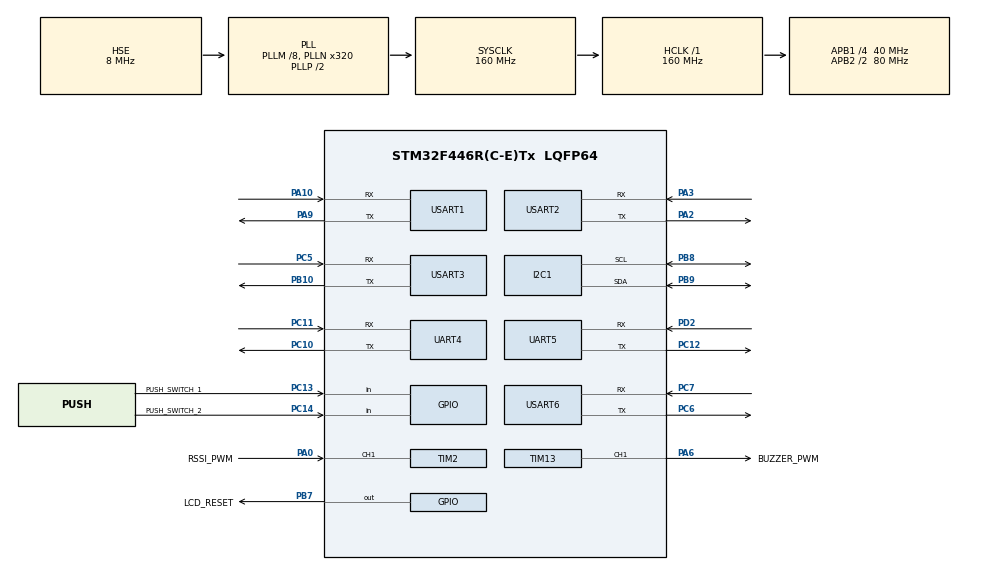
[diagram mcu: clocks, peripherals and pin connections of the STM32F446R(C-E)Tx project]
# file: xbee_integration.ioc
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Dma.Request0=USART1_RX
Dma.Request1=USART1_TX
Dma.Request10=UART4_RX
Dma.Request11=UART4_TX
Dma.Request2=USART2_RX
Dma.Request3=USART2_TX
Dma.Request4=USART3_RX
Dma.Request5=USART3_TX
Dma.Request6=USART6_RX
Dma.Request7=USART6_TX
Dma.Request8=UART5_RX
Dma.Request9=UART5_TX
Dma.UART4_RX.10.Direction=DMA_PERIPH_TO_MEMORY
Dma.UART4_RX.10.FIFOMode=DMA_FIFOMODE_DISABLE
Dma.UART4_RX.10.Instance=DMA1_Stream2
Dma.UART4_RX.10.MemDataAlignment=DMA_MDATAALIGN_BYTE
Dma.UART4_RX.10.MemInc=DMA_MINC_ENABLE
Dma.UART4_RX.10.Mode=DMA_CIRCULAR
Dma.UART4_RX.10.PeriphDataAlignment=DMA_PDATAALIGN_BYTE
Dma.UART4_RX.10.PeriphInc=DMA_PINC_DISABLE
Dma.UART4_RX.10.Priority=DMA_PRIORITY_LOW
Dma.UART4_TX.11.Direction=DMA_MEMORY_TO_PERIPH
Dma.UART4_TX.11.FIFOMode=DMA_FIFOMODE_DISABLE
Dma.UART4_TX.11.Instance=DMA1_Stream4
Dma.UART4_TX.11.MemDataAlignment=DMA_MDATAALIGN_BYTE
Dma.UART4_TX.11.MemInc=DMA_MINC_ENABLE
Dma.UART4_TX.11.Mode=DMA_NORMAL
Dma.UART4_TX.11.PeriphDataAlignment=DMA_PDATAALIGN_BYTE
Dma.UART4_TX.11.PeriphInc=DMA_PINC_DISABLE
Dma.UART4_TX.11.Priority=DMA_PRIORITY_MEDIUM
Dma.UART5_RX.8.Direction=DMA_PERIPH_TO_MEMORY
Dma.UART5_RX.8.FIFOMode=DMA_FIFOMODE_DISABLE
Dma.UART5_RX.8.Instance=DMA1_Stream0
Dma.UART5_RX.8.MemDataAlignment=DMA_MDATAALIGN_BYTE
Dma.UART5_RX.8.MemInc=DMA_MINC_ENABLE
Dma.UART5_RX.8.Mode=DMA_NORMAL
Dma.UART5_RX.8.PeriphDataAlignment=DMA_PDATAALIGN_BYTE
Dma.UART5_RX.8.PeriphInc=DMA_PINC_DISABLE
Dma.UART5_RX.8.Priority=DMA_PRIORITY_LOW
Dma.UART5_TX.9.Direction=DMA_MEMORY_TO_PERIPH
Dma.UART5_TX.9.FIFOMode=DMA_FIFOMODE_DISABLE
Dma.UART5_TX.9.Instance=DMA1_Stream7
Dma.UART5_TX.9.MemDataAlignment=DMA_MDATAALIGN_BYTE
Dma.UART5_TX.9.MemInc=DMA_MINC_ENABLE
Dma.UART5_TX.9.Mode=DMA_NORMAL
Dma.UART5_TX.9.PeriphDataAlignment=DMA_PDATAALIGN_BYTE
Dma.UART5_TX.9.PeriphInc=DMA_PINC_DISABLE
Dma.UART5_TX.9.Priority=DMA_PRIORITY_MEDIUM
Dma.USART1_RX.0.Direction=DMA_PERIPH_TO_MEMORY
Dma.USART1_RX.0.FIFOMode=DMA_FIFOMODE_DISABLE
Dma.USART1_RX.0.Instance=DMA2_Stream2
Dma.USART1_RX.0.MemDataAlignment=DMA_MDATAALIGN_BYTE
Dma.USART1_RX.0.MemInc=DMA_MINC_ENABLE
Dma.USART1_RX.0.Mode=DMA_CIRCULAR
Dma.USART1_RX.0.PeriphDataAlignment=DMA_PDATAALIGN_BYTE
Dma.USART1_RX.0.PeriphInc=DMA_PINC_DISABLE
Dma.USART1_RX.0.Priority=DMA_PRIORITY_MEDIUM
Dma.USART1_TX.1.Direction=DMA_MEMORY_TO_PERIPH
Dma.USART1_TX.1.FIFOMode=DMA_FIFOMODE_DISABLE
Dma.USART1_TX.1.Instance=DMA2_Stream7
Dma.USART1_TX.1.MemDataAlignment=DMA_MDATAALIGN_BYTE
Dma.USART1_TX.1.MemInc=DMA_MINC_ENABLE
Dma.USART1_TX.1.Mode=DMA_NORMAL
Dma.USART1_TX.1.PeriphDataAlignment=DMA_PDATAALIGN_BYTE
Dma.USART1_TX.1.PeriphInc=DMA_PINC_DISABLE
Dma.USART1_TX.1.Priority=DMA_PRIORITY_LOW
Dma.USART2_RX.2.Direction=DMA_PERIPH_TO_MEMORY
Dma.USART2_RX.2.FIFOMode=DMA_FIFOMODE_DISABLE
Dma.USART2_RX.2.Instance=DMA1_Stream5
Dma.USART2_RX.2.MemDataAlignment=DMA_MDATAALIGN_BYTE
Dma.USART2_RX.2.MemInc=DMA_MINC_ENABLE
Dma.USART2_RX.2.Mode=DMA_CIRCULAR
Dma.USART2_RX.2.PeriphDataAlignment=DMA_PDATAALIGN_BYTE
Dma.USART2_RX.2.PeriphInc=DMA_PINC_DISABLE
Dma.USART2_RX.2.Priority=DMA_PRIORITY_MEDIUM
Dma.USART2_TX.3.Direction=DMA_MEMORY_TO_PERIPH
Dma.USART2_TX.3.FIFOMode=DMA_FIFOMODE_DISABLE
Dma.USART2_TX.3.Instance=DMA1_Stream6
Dma.USART2_TX.3.MemDataAlignment=DMA_MDATAALIGN_BYTE
Dma.USART2_TX.3.MemInc=DMA_MINC_ENABLE
Dma.USART2_TX.3.Mode=DMA_NORMAL
Dma.USART2_TX.3.PeriphDataAlignment=DMA_PDATAALIGN_BYTE
Dma.USART2_TX.3.PeriphInc=DMA_PINC_DISABLE
Dma.USART2_TX.3.Priority=DMA_PRIORITY_LOW
Dma.USART3_RX.4.Direction=DMA_PERIPH_TO_MEMORY
Dma.USART3_RX.4.FIFOMode=DMA_FIFOMODE_DISABLE
Dma.USART3_RX.4.Instance=DMA1_Stream1
Dma.USART3_RX.4.MemDataAlignment=DMA_MDATAALIGN_BYTE
Dma.USART3_RX.4.MemInc=DMA_MINC_ENABLE
Dma.USART3_RX.4.Mode=DMA_CIRCULAR
Dma.USART3_RX.4.PeriphDataAlignment=DMA_PDATAALIGN_BYTE
Dma.USART3_RX.4.PeriphInc=DMA_PINC_DISABLE
Dma.USART3_RX.4.Priority=DMA_PRIORITY_VERY_HIGH
Dma.USART3_TX.5.Direction=DMA_MEMORY_TO_PERIPH
Dma.USART3_TX.5.FIFOMode=DMA_FIFOMODE_DISABLE
Dma.USART3_TX.5.Instance=DMA1_Stream3
Dma.USART3_TX.5.MemDataAlignment=DMA_MDATAALIGN_BYTE
Dma.USART3_TX.5.MemInc=DMA_MINC_ENABLE
Dma.USART3_TX.5.Mode=DMA_NORMAL
Dma.USART3_TX.5.PeriphDataAlignment=DMA_PDATAALIGN_BYTE
Dma.USART3_TX.5.PeriphInc=DMA_PINC_DISABLE
Dma.USART3_TX.5.Priority=DMA_PRIORITY_HIGH
Dma.USART6_RX.6.Direction=DMA_PERIPH_TO_MEMORY
Dma.USART6_RX.6.FIFOMode=DMA_FIFOMODE_DISABLE
Dma.USART6_RX.6.Instance=DMA2_Stream1
Dma.USART6_RX.6.MemDataAlignment=DMA_MDATAALIGN_BYTE
Dma.USART6_RX.6.MemInc=DMA_MINC_ENABLE
Dma.USART6_RX.6.Mode=DMA_CIRCULAR
Dma.USART6_RX.6.PeriphDataAlignment=DMA_PDATAALIGN_BYTE
Dma.USART6_RX.6.PeriphInc=DMA_PINC_DISABLE
Dma.USART6_RX.6.Priority=DMA_PRIORITY_VERY_HIGH
Dma.USART6_TX.7.Direction=DMA_MEMORY_TO_PERIPH
Dma.USART6_TX.7.FIFOMode=DMA_FIFOMODE_DISABLE
Dma.USART6_TX.7.Instance=DMA2_Stream6
Dma.USART6_TX.7.MemDataAlignment=DMA_MDATAALIGN_BYTE
Dma.USART6_TX.7.MemInc=DMA_MINC_ENABLE
Dma.USART6_TX.7.Mode=DMA_NORMAL
Dma.USART6_TX.7.PeriphDataAlignment=DMA_PDATAALIGN_BYTE
Dma.USART6_TX.7.PeriphInc=DMA_PINC_DISABLE
Dma.USART6_TX.7.Priority=DMA_PRIORITY_HIGH
Mcu.Family=STM32F4
Mcu.Name=STM32F446R(C-E)Tx
Mcu.Package=LQFP64
NVIC.DMA1_Stream0_IRQn=true\:0\:0\:false\:false\:true\:false\:true\:true
NVIC.DMA1_Stream1_IRQn=true\:0\:0\:false\:false\:true\:false\:true\:true
NVIC.DMA1_Stream2_IRQn=true\:0\:0\:false\:false\:true\:false\:true\:true
NVIC.DMA1_Stream3_IRQn=true\:0\:0\:false\:false\:true\:false\:true\:true
NVIC.DMA1_Stream4_IRQn=true\:0\:0\:false\:false\:true\:false\:true\:true
NVIC.DMA1_Stream5_IRQn=true\:0\:0\:false\:false\:true\:false\:true\:true
NVIC.DMA1_Stream6_IRQn=true\:0\:0\:false\:false\:true\:false\:true\:true
NVIC.DMA1_Stream7_IRQn=true\:0\:0\:false\:false\:true\:false\:true\:true
NVIC.DMA2_Stream1_IRQn=true\:0\:0\:false\:false\:true\:false\:true\:true
NVIC.DMA2_Stream2_IRQn=true\:0\:0\:false\:false\:true\:false\:true\:true
NVIC.DMA2_Stream6_IRQn=true\:0\:0\:false\:false\:true\:false\:true\:true
NVIC.DMA2_Stream7_IRQn=true\:0\:0\:false\:false\:true\:false\:true\:true
NVIC.PriorityGroup=NVIC_PRIORITYGROUP_4
NVIC.UART4_IRQn=true\:0\:0\:false\:false\:true\:true\:true\:true
NVIC.UART5_IRQn=true\:0\:0\:false\:false\:true\:true\:true\:true
NVIC.USART1_IRQn=true\:0\:0\:false\:false\:true\:true\:true\:true
NVIC.USART2_IRQn=true\:0\:0\:false\:false\:true\:true\:true\:true
NVIC.USART3_IRQn=true\:0\:0\:false\:false\:true\:true\:true\:true
NVIC.USART6_IRQn=true\:0\:0\:false\:false\:true\:true\:true\:true
PA0-WKUP.GPIO_Label=RSSI_PWM
PA0-WKUP.Signal=S_TIM2_CH1_ETR
PA10.Mode=Asynchronous
PA10.Signal=USART1_RX
PA13.Mode=Trace_Asynchronous_SW
PA13.Signal=SYS_JTMS-SWDIO
PA14.Mode=Trace_Asynchronous_SW
PA14.Signal=SYS_JTCK-SWCLK
PA2.Mode=Asynchronous
PA2.Signal=USART2_TX
PA3.Mode=Asynchronous
PA3.Signal=USART2_RX
PA6.GPIO_Label=BUZZER_PWM
PA6.Signal=S_TIM13_CH1
PA9.Mode=Asynchronous
PA9.Signal=USART1_TX
PB10.Mode=Asynchronous
PB10.Signal=USART3_TX
PB3.Mode=Trace_Asynchronous_SW
PB3.Signal=SYS_JTDO-SWO
PB7.GPIO_Label=LCD_RESET
PB7.Signal=GPIO_Output
PB8.Mode=I2C
PB8.Signal=I2C1_SCL
PB9.Mode=I2C
PB9.Signal=I2C1_SDA
PC10.Mode=Asynchronous
PC10.Signal=UART4_TX
PC11.Mode=Asynchronous
PC11.Signal=UART4_RX
PC12.Mode=Asynchronous
PC12.Signal=UART5_TX
PC13.GPIO_Label=PUSH_SWITCH_1
PC13.GPIO_PuPd=GPIO_PULLUP
PC13.Signal=GPIO_Input
PC14-OSC32_IN.GPIO_Label=PUSH_SWITCH_2
PC14-OSC32_IN.GPIO_PuPd=GPIO_PULLUP
PC14-OSC32_IN.Signal=GPIO_Input
PC5.Mode=Asynchronous
PC5.Signal=USART3_RX
PC6.Mode=Asynchronous
PC6.Signal=USART6_TX
PC7.Mode=Asynchronous
PC7.Signal=USART6_RX
PD2.Mode=Asynchronous
PD2.Signal=UART5_RX
PH0-OSC_IN.Mode=HSE-External-Clock-Source
PH0-OSC_IN.Signal=RCC_OSC_IN
PH1-OSC_OUT.Mode=HSE-External-Clock-Source
PH1-OSC_OUT.Signal=RCC_OSC_OUT
ProjectManager.HeapSize=0x200
ProjectManager.StackSize=0x400
ProjectManager.TargetToolchain=STM32CubeIDE
RCC.AHBFreq_Value=160000000
RCC.APB1CLKDivider=RCC_HCLK_DIV4
RCC.APB1Freq_Value=40000000
RCC.APB1TimFreq_Value=80000000
RCC.APB2CLKDivider=RCC_HCLK_DIV2
RCC.APB2Freq_Value=80000000
RCC.APB2TimFreq_Value=160000000
RCC.CortexFreq_Value=160000000
RCC.HCLKFreq_Value=160000000
RCC.HSE_VALUE=8000000
RCC.PLLM=8
RCC.PLLN=320
RCC.PLLSourceVirtual=RCC_PLLSOURCE_HSE
RCC.SYSCLKFreq_VALUE=160000000
RCC.SYSCLKSource=RCC_SYSCLKSOURCE_PLLCLK
RCC.USBFreq_Value=160000000
RCC.VCOOutputFreq_Value=320000000
SH.S_TIM13_CH1.0=TIM13_CH1,PWM Generation1 CH1
SH.S_TIM2_CH1_ETR.0=TIM2_CH1,PWM_Input_1
TIM13.Channel=TIM_CHANNEL_1
TIM13.Period=999
TIM13.Prescaler=79
TIM13.Pulse=500
TIM2.Prescaler=79
UART4.VirtualMode=Asynchronous
UART5.VirtualMode=Asynchronous
USART1.VirtualMode=VM_ASYNC
USART2.VirtualMode=VM_ASYNC
USART3.VirtualMode=VM_ASYNC
USART6.VirtualMode=VM_ASYNC
VP_TIM13_VS_ClockSourceINT.Mode=Enable_Timer
board=custom

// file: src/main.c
/* USER CODE BEGIN Header */
/**
  ******************************************************************************
  * @file           : main.c
  * @brief          : Main program body
  ******************************************************************************
  * @attention
  *
  * Copyright (c) 2026 STMicroelectronics.
  * All rights reserved.
  *
  * This software is licensed under terms that can be found in the LICENSE file
  * in the root directory of this software component.
  * If no LICENSE file comes with this software, it is provided AS-IS.
  *
  ******************************************************************************
  */
/* USER CODE END Header */
#include "main.h"

/* USER CODE BEGIN Includes */
#include "app.h"

/* USER CODE END Includes */

I2C_HandleTypeDef hi2c1;

TIM_HandleTypeDef htim2;
TIM_HandleTypeDef htim13;

UART_HandleTypeDef huart4;
UART_HandleTypeDef huart5;
UART_HandleTypeDef huart1;
UART_HandleTypeDef huart2;
UART_HandleTypeDef huart3;
UART_HandleTypeDef huart6;
DMA_HandleTypeDef hdma_uart4_rx;
DMA_HandleTypeDef hdma_uart4_tx;
DMA_HandleTypeDef hdma_uart5_rx;
DMA_HandleTypeDef hdma_uart5_tx;
DMA_HandleTypeDef hdma_usart1_rx;
DMA_HandleTypeDef hdma_usart1_tx;
DMA_HandleTypeDef hdma_usart2_rx;
DMA_HandleTypeDef hdma_usart2_tx;
DMA_HandleTypeDef hdma_usart3_rx;
DMA_HandleTypeDef hdma_usart3_tx;
DMA_HandleTypeDef hdma_usart6_rx;
DMA_HandleTypeDef hdma_usart6_tx;

void SystemClock_Config(void);
static void MX_GPIO_Init(void);
static void MX_DMA_Init(void);
static void MX_TIM13_Init(void);
static void MX_TIM2_Init(void);
static void MX_UART4_Init(void);
static void MX_USART1_UART_Init(void);
static void MX_USART2_UART_Init(void);
static void MX_USART3_UART_Init(void);
static void MX_USART6_UART_Init(void);
static void MX_I2C1_Init(void);
static void MX_UART5_Init(void);

int main(void)
{

  /* MCU Configuration--------------------------------------------------------*/

  /* Reset of all peripherals, Initializes the Flash interface and the Systick. */
  HAL_Init();

  /* Configure the system clock */
  SystemClock_Config();

  /* Initialize all configured peripherals */
  MX_GPIO_Init();
  MX_DMA_Init();
  MX_TIM13_Init();
  MX_TIM2_Init();
  MX_UART4_Init();
  MX_USART1_UART_Init();
  MX_USART2_UART_Init();
  MX_USART3_UART_Init();
  MX_USART6_UART_Init();
  MX_I2C1_Init();
  MX_UART5_Init();
  /* USER CODE BEGIN 2 */
  init();

  /* USER CODE END 2 */

  /* Infinite loop */
  while (1)
  {

    /* USER CODE BEGIN 3 */
    poll();
  }
  /* USER CODE END 3 */
}

void SystemClock_Config(void)
{
  RCC_OscInitTypeDef RCC_OscInitStruct = {0};
  RCC_ClkInitTypeDef RCC_ClkInitStruct = {0};

  /** Configure the main internal regulator output voltage
  */
  __HAL_RCC_PWR_CLK_ENABLE();
  __HAL_PWR_VOLTAGESCALING_CONFIG(PWR_REGULATOR_VOLTAGE_SCALE1);

  /** Initializes the RCC Oscillators according to the specified parameters
  * in the RCC_OscInitTypeDef structure.
  */
  RCC_OscInitStruct.OscillatorType = RCC_OSCILLATORTYPE_HSE;
  RCC_OscInitStruct.HSEState = RCC_HSE_BYPASS;
  RCC_OscInitStruct.PLL.PLLState = RCC_PLL_ON;
  RCC_OscInitStruct.PLL.PLLSource = RCC_PLLSOURCE_HSE;
  RCC_OscInitStruct.PLL.PLLM = 8;
  RCC_OscInitStruct.PLL.PLLN = 320;
  RCC_OscInitStruct.PLL.PLLP = RCC_PLLP_DIV2;
  RCC_OscInitStruct.PLL.PLLQ = 2;
  RCC_OscInitStruct.PLL.PLLR = 2;
  if (HAL_RCC_OscConfig(&RCC_OscInitStruct) != HAL_OK)
  {
    Error_Handler();
  }

  /** Initializes the CPU, AHB and APB buses clocks
  */
  RCC_ClkInitStruct.ClockType = RCC_CLOCKTYPE_HCLK|RCC_CLOCKTYPE_SYSCLK
                              |RCC_CLOCKTYPE_PCLK1|RCC_CLOCKTYPE_PCLK2;
  RCC_ClkInitStruct.SYSCLKSource = RCC_SYSCLKSOURCE_PLLCLK;
  RCC_ClkInitStruct.AHBCLKDivider = RCC_SYSCLK_DIV1;
  RCC_ClkInitStruct.APB1CLKDivider = RCC_HCLK_DIV4;
  RCC_ClkInitStruct.APB2CLKDivider = RCC_HCLK_DIV2;

  if (HAL_RCC_ClockConfig(&RCC_ClkInitStruct, FLASH_LATENCY_5) != HAL_OK)
  {
    Error_Handler();
  }
}

static void MX_I2C1_Init(void)
{

  hi2c1.Instance = I2C1;
  hi2c1.Init.ClockSpeed = 100000;
  hi2c1.Init.DutyCycle = I2C_DUTYCYCLE_2;
  hi2c1.Init.OwnAddress1 = 0;
  hi2c1.Init.AddressingMode = I2C_ADDRESSINGMODE_7BIT;
  hi2c1.Init.DualAddressMode = I2C_DUALADDRESS_DISABLE;
  hi2c1.Init.OwnAddress2 = 0;
  hi2c1.Init.GeneralCallMode = I2C_GENERALCALL_DISABLE;
  hi2c1.Init.NoStretchMode = I2C_NOSTRETCH_DISABLE;
  if (HAL_I2C_Init(&hi2c1) != HAL_OK)
  {
    Error_Handler();
  }

}

static void MX_TIM2_Init(void)
{

  TIM_SlaveConfigTypeDef sSlaveConfig = {0};
  TIM_IC_InitTypeDef sConfigIC = {0};
  TIM_MasterConfigTypeDef sMasterConfig = {0};

  htim2.Instance = TIM2;
  htim2.Init.Prescaler = 79;
  htim2.Init.CounterMode = TIM_COUNTERMODE_UP;
  htim2.Init.Period = 4294967295;
  htim2.Init.ClockDivision = TIM_CLOCKDIVISION_DIV1;
  htim2.Init.AutoReloadPreload = TIM_AUTORELOAD_PRELOAD_DISABLE;
  if (HAL_TIM_IC_Init(&htim2) != HAL_OK)
  {
    Error_Handler();
  }
  sSlaveConfig.SlaveMode = TIM_SLAVEMODE_RESET;
  sSlaveConfig.InputTrigger = TIM_TS_TI1FP1;
  sSlaveConfig.TriggerPolarity = TIM_INPUTCHANNELPOLARITY_RISING;
  sSlaveConfig.TriggerPrescaler = TIM_ICPSC_DIV1;
  sSlaveConfig.TriggerFilter = 0;
  if (HAL_TIM_SlaveConfigSynchro(&htim2, &sSlaveConfig) != HAL_OK)
  {
    Error_Handler();
  }
  sConfigIC.ICPolarity = TIM_INPUTCHANNELPOLARITY_RISING;
  sConfigIC.ICSelection = TIM_ICSELECTION_DIRECTTI;
  sConfigIC.ICPrescaler = TIM_ICPSC_DIV1;
  sConfigIC.ICFilter = 0;
  if (HAL_TIM_IC_ConfigChannel(&htim2, &sConfigIC, TIM_CHANNEL_1) != HAL_OK)
  {
    Error_Handler();
  }
  sConfigIC.ICPolarity = TIM_INPUTCHANNELPOLARITY_FALLING;
  sConfigIC.ICSelection = TIM_ICSELECTION_INDIRECTTI;
  if (HAL_TIM_IC_ConfigChannel(&htim2, &sConfigIC, TIM_CHANNEL_2) != HAL_OK)
  {
    Error_Handler();
  }
  sMasterConfig.MasterOutputTrigger = TIM_TRGO_RESET;
  sMasterConfig.MasterSlaveMode = TIM_MASTERSLAVEMODE_DISABLE;
  if (HAL_TIMEx_MasterConfigSynchronization(&htim2, &sMasterConfig) != HAL_OK)
  {
    Error_Handler();
  }

}

static void MX_TIM13_Init(void)
{

  TIM_OC_InitTypeDef sConfigOC = {0};

  htim13.Instance = TIM13;
  htim13.Init.Prescaler = 79;
  htim13.Init.CounterMode = TIM_COUNTERMODE_UP;
  htim13.Init.Period = 999;
  htim13.Init.ClockDivision = TIM_CLOCKDIVISION_DIV1;
  htim13.Init.AutoReloadPreload = TIM_AUTORELOAD_PRELOAD_DISABLE;
  if (HAL_TIM_Base_Init(&htim13) != HAL_OK)
  {
    Error_Handler();
  }
  if (HAL_TIM_PWM_Init(&htim13) != HAL_OK)
  {
    Error_Handler();
  }
  sConfigOC.OCMode = TIM_OCMODE_PWM1;
  sConfigOC.Pulse = 500;
  sConfigOC.OCPolarity = TIM_OCPOLARITY_HIGH;
  sConfigOC.OCFastMode = TIM_OCFAST_DISABLE;
  if (HAL_TIM_PWM_ConfigChannel(&htim13, &sConfigOC, TIM_CHANNEL_1) != HAL_OK)
  {
    Error_Handler();
  }
  HAL_TIM_MspPostInit(&htim13);

}

static void MX_UART4_Init(void)
{

  huart4.Instance = UART4;
  huart4.Init.BaudRate = 115200;
  huart4.Init.WordLength = UART_WORDLENGTH_8B;
  huart4.Init.StopBits = UART_STOPBITS_1;
  huart4.Init.Parity = UART_PARITY_NONE;
  huart4.Init.Mode = UART_MODE_TX_RX;
  huart4.Init.HwFlowCtl = UART_HWCONTROL_NONE;
  huart4.Init.OverSampling = UART_OVERSAMPLING_16;
  if (HAL_UART_Init(&huart4) != HAL_OK)
  {
    Error_Handler();
  }

}

static void MX_UART5_Init(void)
{

  huart5.Instance = UART5;
  huart5.Init.BaudRate = 115200;
  huart5.Init.WordLength = UART_WORDLENGTH_8B;
  huart5.Init.StopBits = UART_STOPBITS_1;
  huart5.Init.Parity = UART_PARITY_NONE;
  huart5.Init.Mode = UART_MODE_TX_RX;
  huart5.Init.HwFlowCtl = UART_HWCONTROL_NONE;
  huart5.Init.OverSampling = UART_OVERSAMPLING_16;
  if (HAL_UART_Init(&huart5) != HAL_OK)
  {
    Error_Handler();
  }

}

static void MX_USART1_UART_Init(void)
{

  huart1.Instance = USART1;
  huart1.Init.BaudRate = 115200;
  huart1.Init.WordLength = UART_WORDLENGTH_8B;
  huart1.Init.StopBits = UART_STOPBITS_1;
  huart1.Init.Parity = UART_PARITY_NONE;
  huart1.Init.Mode = UART_MODE_TX_RX;
  huart1.Init.HwFlowCtl = UART_HWCONTROL_NONE;
  huart1.Init.OverSampling = UART_OVERSAMPLING_16;
  if (HAL_UART_Init(&huart1) != HAL_OK)
  {
    Error_Handler();
  }

}

static void MX_USART2_UART_Init(void)
{

  huart2.Instance = USART2;
  huart2.Init.BaudRate = 115200;
  huart2.Init.WordLength = UART_WORDLENGTH_8B;
  huart2.Init.StopBits = UART_STOPBITS_1;
  huart2.Init.Parity = UART_PARITY_NONE;
  huart2.Init.Mode = UART_MODE_TX_RX;
  huart2.Init.HwFlowCtl = UART_HWCONTROL_NONE;
  huart2.Init.OverSampling = UART_OVERSAMPLING_16;
  if (HAL_UART_Init(&huart2) != HAL_OK)
  {
    Error_Handler();
  }

}

static void MX_USART3_UART_Init(void)
{

  huart3.Instance = USART3;
  huart3.Init.BaudRate = 115200;
  huart3.Init.WordLength = UART_WORDLENGTH_8B;
  huart3.Init.StopBits = UART_STOPBITS_1;
  huart3.Init.Parity = UART_PARITY_NONE;
  huart3.Init.Mode = UART_MODE_TX_RX;
  huart3.Init.HwFlowCtl = UART_HWCONTROL_NONE;
  huart3.Init.OverSampling = UART_OVERSAMPLING_16;
  if (HAL_UART_Init(&huart3) != HAL_OK)
  {
    Error_Handler();
  }

}

static void MX_USART6_UART_Init(void)
{

  huart6.Instance = USART6;
  huart6.Init.BaudRate = 115200;
  huart6.Init.WordLength = UART_WORDLENGTH_8B;
  huart6.Init.StopBits = UART_STOPBITS_1;
  huart6.Init.Parity = UART_PARITY_NONE;
  huart6.Init.Mode = UART_MODE_TX_RX;
  huart6.Init.HwFlowCtl = UART_HWCONTROL_NONE;
  huart6.Init.OverSampling = UART_OVERSAMPLING_16;
  if (HAL_UART_Init(&huart6) != HAL_OK)
  {
    Error_Handler();
  }

}

static void MX_DMA_Init(void)
{

  /* DMA controller clock enable */
  __HAL_RCC_DMA2_CLK_ENABLE();
  __HAL_RCC_DMA1_CLK_ENABLE();

  /* DMA interrupt init */
  /* DMA1_Stream0_IRQn interrupt configuration */
  HAL_NVIC_SetPriority(DMA1_Stream0_IRQn, 0, 0);
  HAL_NVIC_EnableIRQ(DMA1_Stream0_IRQn);
  /* DMA1_Stream1_IRQn interrupt configuration */
  HAL_NVIC_SetPriority(DMA1_Stream1_IRQn, 0, 0);
  HAL_NVIC_EnableIRQ(DMA1_Stream1_IRQn);
  /* DMA1_Stream2_IRQn interrupt configuration */
  HAL_NVIC_SetPriority(DMA1_Stream2_IRQn, 0, 0);
  HAL_NVIC_EnableIRQ(DMA1_Stream2_IRQn);
  /* DMA1_Stream3_IRQn interrupt configuration */
  HAL_NVIC_SetPriority(DMA1_Stream3_IRQn, 0, 0);
  HAL_NVIC_EnableIRQ(DMA1_Stream3_IRQn);
  /* DMA1_Stream4_IRQn interrupt configuration */
  HAL_NVIC_SetPriority(DMA1_Stream4_IRQn, 0, 0);
  HAL_NVIC_EnableIRQ(DMA1_Stream4_IRQn);
  /* DMA1_Stream5_IRQn interrupt configuration */
  HAL_NVIC_SetPriority(DMA1_Stream5_IRQn, 0, 0);
  HAL_NVIC_EnableIRQ(DMA1_Stream5_IRQn);
  /* DMA1_Stream6_IRQn interrupt configuration */
  HAL_NVIC_SetPriority(DMA1_Stream6_IRQn, 0, 0);
  HAL_NVIC_EnableIRQ(DMA1_Stream6_IRQn);
  /* DMA1_Stream7_IRQn interrupt configuration */
  HAL_NVIC_SetPriority(DMA1_Stream7_IRQn, 0, 0);
  HAL_NVIC_EnableIRQ(DMA1_Stream7_IRQn);
  /* DMA2_Stream1_IRQn interrupt configuration */
  HAL_NVIC_SetPriority(DMA2_Stream1_IRQn, 0, 0);
  HAL_NVIC_EnableIRQ(DMA2_Stream1_IRQn);
  /* DMA2_Stream2_IRQn interrupt configuration */
  HAL_NVIC_SetPriority(DMA2_Stream2_IRQn, 0, 0);
  HAL_NVIC_EnableIRQ(DMA2_Stream2_IRQn);
  /* DMA2_Stream6_IRQn interrupt configuration */
  HAL_NVIC_SetPriority(DMA2_Stream6_IRQn, 0, 0);
  HAL_NVIC_EnableIRQ(DMA2_Stream6_IRQn);
  /* DMA2_Stream7_IRQn interrupt configuration */
  HAL_NVIC_SetPriority(DMA2_Stream7_IRQn, 0, 0);
  HAL_NVIC_EnableIRQ(DMA2_Stream7_IRQn);

}

static void MX_GPIO_Init(void)
{
  GPIO_InitTypeDef GPIO_InitStruct = {0};

  /* GPIO Ports Clock Enable */
  __HAL_RCC_GPIOC_CLK_ENABLE();
  __HAL_RCC_GPIOH_CLK_ENABLE();
  __HAL_RCC_GPIOA_CLK_ENABLE();
  __HAL_RCC_GPIOB_CLK_ENABLE();
  __HAL_RCC_GPIOD_CLK_ENABLE();

  /*Configure GPIO pin Output Level */
  HAL_GPIO_WritePin(LCD_RESET_GPIO_Port, LCD_RESET_Pin, GPIO_PIN_RESET);

  /*Configure GPIO pin : PUSH_SWITCH_1_Pin */
  GPIO_InitStruct.Pin = PUSH_SWITCH_1_Pin;
  GPIO_InitStruct.Mode = GPIO_MODE_INPUT;
  GPIO_InitStruct.Pull = GPIO_PULLUP;
  HAL_GPIO_Init(PUSH_SWITCH_1_GPIO_Port, &GPIO_InitStruct);

  /*Configure GPIO pin : PUSH_SWITCH_2_Pin */
  GPIO_InitStruct.Pin = PUSH_SWITCH_2_Pin;
  GPIO_InitStruct.Mode = GPIO_MODE_INPUT;
  GPIO_InitStruct.Pull = GPIO_PULLUP;
  HAL_GPIO_Init(PUSH_SWITCH_2_GPIO_Port, &GPIO_InitStruct);

  /*Configure GPIO pin : LCD_RESET_Pin */
  GPIO_InitStruct.Pin = LCD_RESET_Pin;
  GPIO_InitStruct.Mode = GPIO_MODE_OUTPUT_PP;
  GPIO_InitStruct.Pull = GPIO_NOPULL;
  GPIO_InitStruct.Speed = GPIO_SPEED_FREQ_LOW;
  HAL_GPIO_Init(LCD_RESET_GPIO_Port, &GPIO_InitStruct);

}

void Error_Handler(void)
{
  __disable_irq();
  while (1)
  {
  }
}
